# N572F065_v3 register map
File version: 1.0
Registers are 32-bit, read-write, reset 0x0 unless marked. A register's access mark holds for its fields unless they carry their own. Offsets are from the block's base; [hi:lo] are bit positions; {n}, {i} and the like mark numbered series; 'fields as' and 'values as' point back to an identical list.

## ADC — ADC Register Map
Base 0x400E0000
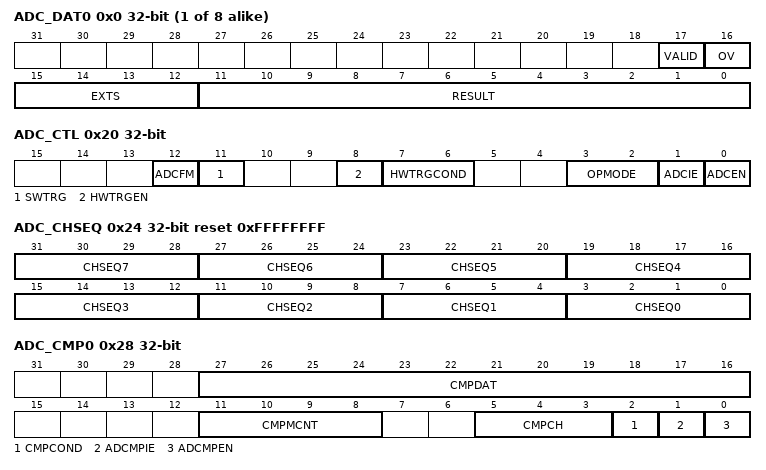
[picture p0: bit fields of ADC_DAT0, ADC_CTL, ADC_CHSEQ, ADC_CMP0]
{0x0+4i} ADC_DAT{i} ro (i=0..7) — A/D Data Register for the channel defined in CHSEQ0
  [17] VALID — Valid Flag. This bit is set to 1 when corresponding channel analog input conversion is completed and cleared by hardware after ADC_DAT register is read.
    0=Data in RESULT are not valid; 1=Data in RESULT are valid
  [16] OV — Over Run Flag. If converted data in RESULT[11:0] have not been read before new conversion result is loaded to this register, OV is set to 1. It is cleared by hardware after ADC_DAT register is read.
    0=Data in RESULT are recent conversion result; 1=Data in RESULT are overwritten
  [15:12] EXTS — Extension Bits Of RESULT for Different Data Format. If ADCFM is "0", EXTS all are read as "0". If ADCFM is "1", EXTS all are read as bit RESULT[11].
  [11:0] RESULT — A/D Conversion Result. This field contains the 12-bit conversion result. Its data format is defined by ADCFM bit.
0x20 ADC_CTL — A/D Control Register
  [12] ADCFM — Data Format Of ADC Conversion Result
    0=Unsigned; 1=2'Complemet
  [11] SWTRG — A/D Conversion Start. Note: SWTRG bit can be set to 1 from three sources: software write and external pin STADC. SWTRG is cleared to 0 by hardware automatically at the end of single mode and single-cycle scan mode on specified channel. In continuous scan mode, A/D conversion is continuously performed sequentially until software writes 0 to this bit or chip resets.
    0=Conversion is stopped and A/D converter enters idle state; 1=Start conversion
  [8] HWTRGEN — Trigger Enable. Enable or disable triggering of A/D conversion by external STADC pin.
    0=Disable; 1=Enable
  [7:6] HWTRGCOND — Trigger Condition. These two bits decide external pin STADC trigger event is level or edge. The signal must be kept at stable state at least 8 PCLKs for level trigger and 4 PCLKs at high and low state.
    0=Low level; 1=High level; 2=Falling edge; 3=Positive edge
  [3:2] OPMODE — A/D Converter Operation Mode. When changing the operation mode, software should disable SWTRG bit firstly.
    0=Single conversion; 2=Single-cycle scan; 3=Continuous scan
  [1] ADCIE — A/D Interrupt Enable. A/D conversion end interrupt request is generated if ADCIE bit is set to 1.
    0=Disable A/D interrupt function; 1=Enable A/D interrupt function
  [0] ADCEN — A/D Converter Enable. Before starting A/D conversion function, this bit should be set to 1. Clear it to 0 to disable A/D converter analog circuit power consumption.
    0=Disable; 1=Enable
0x24 ADC_CHSEQ reset 0xFFFFFFFF — A/D Channel Sequence Register
  [4n+3:4n] CHSEQ{n} (n=3..7) — Select Channel N As The {n+1}th Conversion In Scan Sequence. The definition of channel selection is the same as CHSEQ0.
  [11:8] CHSEQ2 — Select Channel N As The 3rd Conversion In Scan Sequence. The definition of channel selection is the same as CHSEQ0.
  [7:4] CHSEQ1 — Select Channel N As The 2nd Conversion In Scan Sequence. The definition of channel selection is the same as CHSEQ0.
  [3:0] CHSEQ0 — Select Channel N As The 1st Conversion In Scan Sequence
    9=no channel is selected, scan sequence end
0x28 ADC_CMP0 — A/D Compare Register 0
  [27:16] CMPDAT — Compare Data. The 12 bits data are used to compare with conversion result of specified channel. Software can use it to monitor the external analog input pin voltage transition in scan mode without imposing a load on software. The data format should be consistent with the setting of ADCFM bit.
  [11:8] CMPMCNT — Compare Match Count. When the specified A/D channel analog conversion result matches the comparing condition, the internal match counter will increase 1. When the internal counter achieves the setting, (CMPMCNT+1) hardware will set the ADCMPF bit.
  [5:3] CMPCH — Compare Channel Selection
    {v}=Channel {v} conversion result is selected to be compared (v=0..7)
  [2] CMPCOND — Compare Condition
    0=ADCMPFx bit is set if conversion result is less than CMPDAT[11:0]; 1=ADCMPFx bit is set if conversion result is greater or equal to CMPDAT[11:0],
  [1] ADCMPIE — Compare Interrupt Enable. When converted data in RESULT is less (or greater) than the compare data CMPDAT[11:0], ADCMPF bit is asserted. If ADCMPIE is set to 1, a compare interrupt request is generated.
    0=Disable; 1=Enable
  [0] ADCMPEN — Compare Enable. Set this bit to 1 to enable the comparison CMPDAT[11:0] with specified channel conversion result when converted data is loaded into ADC_DAT register.
    0=Disable compare; 1=Enable compare
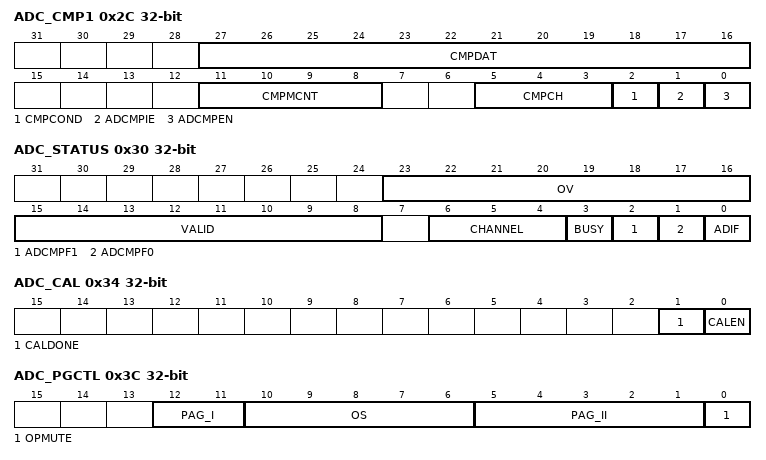
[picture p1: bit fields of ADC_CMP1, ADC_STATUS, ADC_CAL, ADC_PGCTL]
0x2C ADC_CMP1 — A/D Compare Register 0
  fields as ADC_CMP0
0x30 ADC_STATUS — A/D Status Register
  [23:16] OV — Over Run Flag. It is a mirror to OV bit in ADC_DATn.
  [15:8] VALID — Data Valid Flag. It is a mirror of VALID bit in ADC_DATn.
  [6:4] CHANNEL — Current Conversion Channel. It is read only.
  [3] BUSY — BUSY/IDLE. This bit is mirror of SWTRG bit in ADC_CTL. It is read only.
    0=A/D converter is in idle state; 1=A/D converter is busy at conversion
  [2] ADCMPF1 — Compare Flag. When the selected channel A/D conversion result meets setting conditions in ADC_CMP1, then this bit is set to 1. And it is cleared by write 1.
    0=Converted result RESULT in ADC_DAT does not meet ADC_CMP1 setting; 1=Converted result RESULT in ADC_DAT meets ADC_CMP1 setting,
  [1] ADCMPF0 — Compare Flag. When the selected channel A/D conversion result meets setting conditions in ADC_CMP0, then this bit is set to 1. And it is cleared by write 1.
    0=Converted result RESULT in ADC_DAT does not meet ADC_CMP0 setting; 1=Converted result RESULT in ADC_DAT meets ADC_CMP0 setting,
  [0] ADIF — A/D Conversion End Flag. A status flag that indicates the end of A/D conversion. ADIF is set to 1 under the following two conditions: When A/D conversion ends in single mode, When A/D conversion ends on all channels specified by channel sequence register in scan mode. And it is cleared when 1 is written.
0x34 ADC_CAL — A/D Calibration Register
  [1] CALDONE ro — Calibration is Done (read only). When 0 is written to CALEN bit, CALDONE bit is cleared by hardware immediately and be set to 1 after 96 ADC clocks. It is a read only bit.
    0=A/D converter has not been calibrated or calibration is in progress if CALEN bit is set; 1=A/D converter self-calibration is done
  [0] CALEN — Self-Calibration Enable. Software can set this bit to 1 enables A/D converter to do self-calibration function. It needs 127 ADC clocks to complete calibration. This bit must be kept at 1 after CALDONE asserted. Clearing this bit will disable self-calibration function.
    0=Disable self-calibration; 1=Enable self-calibration
0x3C ADC_PGCTL — ADC Pre-amplifier Gain Control Register
  [12:11] PAG_I — Gain Setting Bits for the First Stage Of Pre-Amp
    0=-6 dB,; 1=0 dB,; 2=8 dB,; 3=14 dB,
  [10:6] OS — Configuration for Pre-Amp OP Offset Bias Compensation Voltage. There are 32 levels and 2mV per level @ 5V condition.
  [5:1] PAG_II — Gain Setting Bits for the Second Stage Of Pre-Amp
    0=0 dB,; 1=16 dB,; 2=17 dB,; 3=18 dB,; 31=46 dB
  [0] OPMUTE — Mute Control of First Stage Pre-Amp for Offset Bias Calibration. When this bit is set as "1", two input end of first stage pre-amp will be shorted, and feedback resistor of this stage will be shorted.
    0=open; 1=short
